# apollo3p register map
Vendor: Ambiq Micro; Series: Apollo; File version: 1.0
CPU: CM4 r1p0, little endian, MPU, FPU, I-cache, D-cache, VTOR, ITCM, DTCM, 3 interrupt priority bits, 0 interrupts
Registers are 32-bit, read-write, reset 0x0 unless marked. A register's access mark holds for its fields unless they carry their own. Offsets are from the block's base; [hi:lo] are bit positions; {n}, {i} and the like mark numbered series; 'fields as' and 'values as' point back to an identical list.

## SECURITY — Security Interfaces
Base 0x40030000
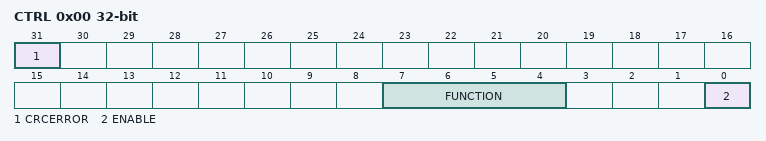
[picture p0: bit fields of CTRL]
0x00 CTRL — Control
  [31] CRCERROR — CRC Error Status - Set to 1 if an error occurs during a CRC operation. Cleared when CTRL register is written (with any value). Usually indicates an invalid address range.
  [7:4] FUNCTION — Function Select
    0=CRC32 (Perform CRC32 operation); 1=RAND (DMA pseudo-random number stream based on CRC value); 2=GENADDR (Generate DMA stream based on address)
  [0] ENABLE — Function Enable. Software should set the ENABLE bit to initiate a CRC operation. Hardware will clear the ENABLE bit upon completion.
0x10 SRCADDR — Source Address
  [31:0] ADDR — Source Buffer Address. Address may be byte aligned, but the length must be a multiple of 4 bits.
0x20 LEN — Length
  [23:2] LEN — Buffer size (bottom two bits assumed to be zero to ensure a multiple of 4 bytes)
0x30 RESULT — CRC Seed/Result
  [31:0] CRC — CRC Seed/Result. Software must seed the CRC with 0xFFFFFFFF before starting a CRC operation (unless the CRC is continued from a previous operation).
0x78 LOCKCTRL — LOCK Control
  [7:0] SELECT — LOCK Function Select register.
    1=CUSTOMER_KEY (Unlock Customer Key (access to top half of INFO0)); 0=NONE (Lock Control should be set to NONE when not in use.)
0x7C LOCKSTAT — LOCK Status
  [31:0] STATUS — LOCK Status register. This register is a bit mask for which resources are currently unlocked. These bits are one-hot per resource.
    1=CUSTOMER_KEY (Customer Key is unlocked (access is granted to top half of INFO0)); 0=NONE (No resources are unlocked)
{0x80+4i} KEY{i} (i=0..3)
  [31:0] KEY{i} — Bits [{32i+31}:{32i}] of the 128-bit key should be written to this register. To protect key values, the register always returns 0x00000000.

## VCOMP — Voltage Comparator
Base 0x4000C000
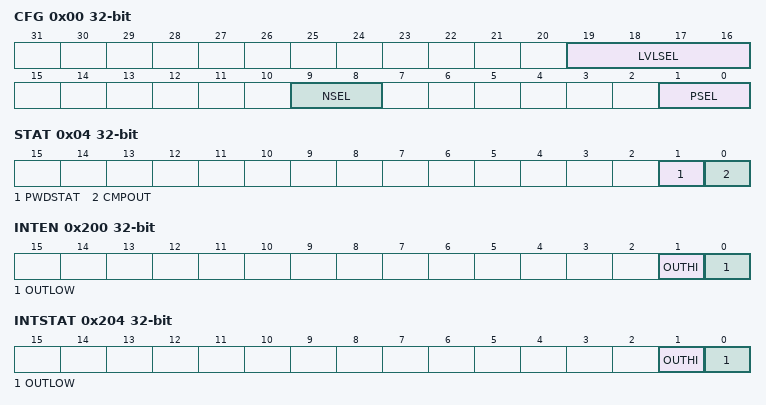
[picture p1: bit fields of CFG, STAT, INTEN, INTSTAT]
0x00 CFG — The Voltage Comparator Configuration Register contains the software control for selecting between the 4 options for the positive input as well as the multiple options for the reference input.
  [19:16] LVLSEL — When the reference input NSEL is set to NSEL_DAC, this bit field selects the voltage level for the negative input to the comparator.
    0=0P58V (Set Reference input to 0.58 Volts.); 1=0P77V (Set Reference input to 0.77 Volts.); 2=0P97V (Set Reference input to 0.97 Volts.); 3=1P16V (Set Reference input to 1.16 Volts.); 4=1P35V (Set Reference input to 1.35 Volts.); 5=1P55V (Set Reference input to 1.55 Volts.); 6=1P74V (Set Reference input to 1.74 Volts.); 7=1P93V (Set Reference input to 1.93 Volts.); 8=2P13V (Set Reference input to 2.13 Volts.); 9=2P32V (Set Reference input to 2.32 Volts.); 10=2P51V (Set Reference input to 2.51 Volts.); 11=2P71V (Set Reference input to 2.71 Volts.); 12=2P90V (Set Reference input to 2.90 Volts.); 13=3P09V (Set Reference input to 3.09 Volts.); 14=3P29V (Set Reference input to 3.29 Volts.); 15=3P48V (Set Reference input to 3.48 Volts.)
  [9:8] NSEL — This bit field selects the negative input to the comparator.
    0=VREFEXT1 (Use external reference 1 for reference input.); 1=VREFEXT2 (Use external reference 2 for reference input.); 2=VREFEXT3 (Use external reference 3 for reference input.); 3=DAC (Use DAC output selected by LVLSEL for reference input.)
  [1:0] PSEL — This bit field selects the positive input to the comparator.
    0=VDDADJ (Use VDDADJ for the positive input.); 1=VTEMP (Use the temperature sensor output for the positive input. Note: If this channel is selected for PSEL, the bandgap circuit required for temperature comparisons will automatically turn on. The bandgap circuit requires 11 us to stabilize.); 2=VEXT1 (Use external voltage 0 for positive input.); 3=VEXT2 (Use external voltage 1 for positive input.)
0x04 STAT — Status
  [1] PWDSTAT — This bit indicates the power down state of the voltage comparator.
    1=POWERED_DOWN (The voltage comparator is powered down.)
  [0] CMPOUT — This bit is 1 if the positive input of the comparator is greater than the negative input.
    0=VOUT_LOW (The negative input of the comparator is greater than the positive input.); 1=VOUT_HIGH (The positive input of the comparator is greater than the negative input.)
0x08 PWDKEY — Write a value of 0x37 to unlock, write any other value to lock. This register also indicates lock status when read. When in the unlocked state (i.e. 0x37 has been written), it reads as 1. When in the locked state, it reads as 0.
  [31:0] PWDKEY — Key register value.
    55=Key (Key value to unlock the register.)
0x200 INTEN — Set bits in this register to allow this module to generate the corresponding interrupt.
  [1] OUTHI — This bit is the vcompout high interrupt.
  [0] OUTLOW — This bit is the vcompout low interrupt.
0x204 INTSTAT — Read bits from this register to discover the cause of a recent interrupt.
  fields as INTEN
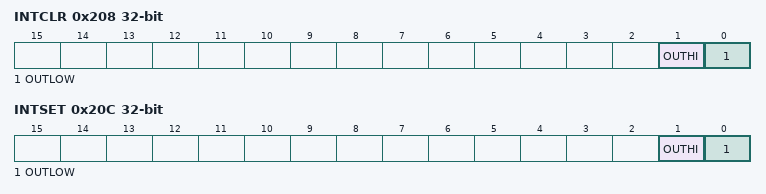
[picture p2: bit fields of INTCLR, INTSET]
0x208 INTCLR — Write a 1 to a bit in this register to clear the interrupt status associated with that bit.
  fields as INTEN
0x20C INTSET — Write a 1 to a bit in this register to instantly generate an interrupt from this module. (Generally used for testing purposes).
  fields as INTEN

## WDT — Watchdog Timer
Base 0x40024000
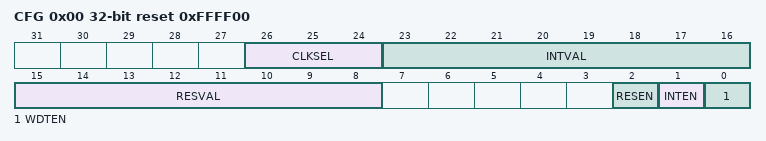
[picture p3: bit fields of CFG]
0x00 CFG reset 0xFFFF00 — This is the configuration register for the watch dog timer. It controls the enable, interrupt set, clocks for the timer, the compare values for the counters to trigger a reset or interrupt. This register can only be written to if the watch dog timer is unlocked (WDTLOCK is not set).
  [26:24] CLKSEL — Select the frequency for the WDT. All values not enumerated below are undefined.
    0=OFF (Low Power Mode. This setting disables the watch dog timer.); 1=128HZ (128 Hz LFRC clock.); 2=16HZ (16 Hz LFRC clock.); 3=1HZ (1 Hz LFRC clock.); 4=1_16HZ (1/16th Hz LFRC clock.)
  [23:16] INTVAL — This bit field is the compare value for counter bits 7:0 to generate a watchdog interrupt.
  [15:8] RESVAL — This bit field is the compare value for counter bits 7:0 to generate a watchdog reset. This will cause a software reset.
  [2] RESEN — This bit field enables the WDT reset. This needs to be set together with the WDREN bit in REG_RSTGEN_CFG register (in reset gen) to trigger the reset.
  [1] INTEN — This bit field enables the WDT interrupt. Note : This bit must be set before the interrupt status bit will reflect a watchdog timer expiration. The IER interrupt register must also be enabled for a WDT interrupt to be sent to the NVIC.
  [0] WDTEN — This bit field enables the WDT.
0x04 RSTRT — This register will Restart the watchdog timer. Writing a special key value into this register will result in the watch dog timer being reset, so that the count will start again. It is expected that the software will periodically write to this register to indicate that the system is functional. The watch dog timer can continue running when the system is in deep sleep, and the interrupt will trigger the wake. After the wake, the core can reset the watch dog timer.
  [7:0] RSTRT — Writing 0xB2 to WDTRSTRT restarts the watchdog timer. This is a write only register. Reading this register will only provide all 0.
    178=KEYVALUE (This is the key value to write to WDTRSTRT to restart the WDT. This is a write only register.)
0x08 LOCK — This register locks the watch dog timer. Once it is locked, the configuration register (WDTCFG) for watch dog timer cannot be written to.
  [7:0] LOCK — Writing 0x3A locks the watchdog timer. Once locked, the WDTCFG reg cannot be written and WDTEN is set.
    58=KEYVALUE (This is the key value to write to WDTLOCK to lock the WDT.)
0x0C COUNT — This register holds the current count for the watch dog timer. This is a read only register. SW cannot set the value in the counter, but can reset it.
  [7:0] COUNT — Read-Only current value of the WDT counter
0x200 INTEN — Set bits in this register to allow this module to generate the corresponding interrupt.
  [0] WDTINT — Watchdog Timer Interrupt.
0x204 INTSTAT — Read bits from this register to discover the cause of a recent interrupt.
  [0] WDTINT — Watchdog Timer Interrupt.
0x208 INTCLR — Write a 1 to a bit in this register to clear the interrupt status associated with that bit.
  [0] WDTINT — Watchdog Timer Interrupt.
0x20C INTSET — Write a 1 to a bit in this register to instantly generate an interrupt from this module. (Generally used for testing purposes).
  [0] WDTINT — Watchdog Timer Interrupt.
